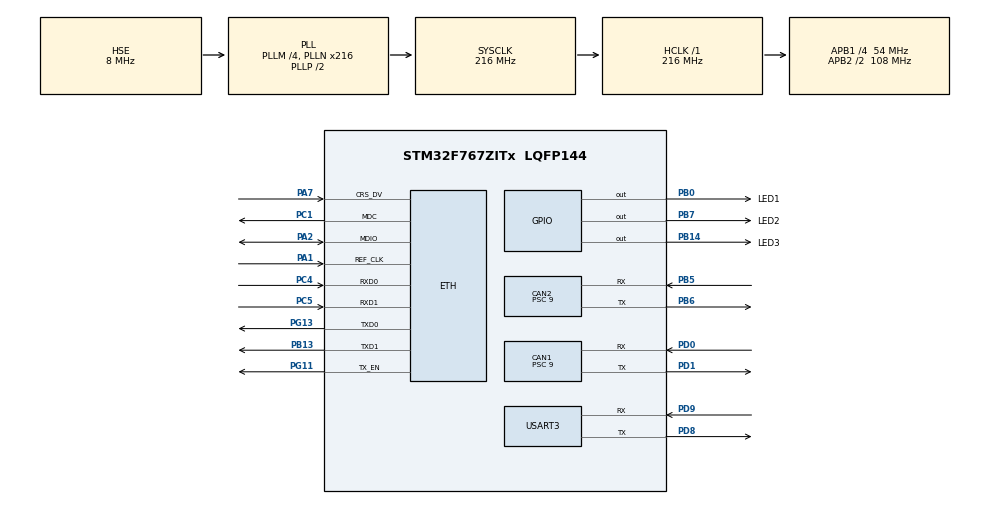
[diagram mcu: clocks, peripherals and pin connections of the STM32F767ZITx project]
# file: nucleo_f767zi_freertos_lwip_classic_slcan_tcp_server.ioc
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CAN1.ABOM=ENABLE
CAN1.BS1=CAN_BS1_6TQ
CAN1.BS2=CAN_BS2_5TQ
CAN1.CalculateBaudRate=499999
CAN1.CalculateTimeBit=2000
CAN1.CalculateTimeQuantum=166.66666666666669
CAN1.NART=ENABLE
CAN1.Prescaler=9
CAN1.TXFP=ENABLE
CAN2.ABOM=ENABLE
CAN2.BS1=CAN_BS1_6TQ
CAN2.BS2=CAN_BS2_5TQ
CAN2.CalculateBaudRate=499999
CAN2.CalculateTimeBit=2000
CAN2.CalculateTimeQuantum=166.66666666666669
CAN2.NART=ENABLE
CAN2.Prescaler=9
CAN2.TXFP=ENABLE
CORTEX_M7.default_mode_Activation=1
ETH.MediaInterface=HAL_ETH_RMII_MODE
FREERTOS.Tasks01=defaultTask,0,256,StartDefaultTask,Default,NULL,Dynamic,NULL,NULL
FREERTOS.configUSE_NEWLIB_REENTRANT=1
LWIP.BSP.number=1
LWIP.Version=v2.1.2_Cube
LWIP0.BSP.STBoard=false
LWIP0.BSP.api=BSP_COMPONENT_DRIVER
LWIP0.BSP.component=LAN8742
LWIP0.BSP.instance=LAN8742
LWIP0.BSP.name=Driver_PHY
LWIP0.BSP.semaphore=S_LAN8742
LWIP0.BSP.solution=LAN8742
Mcu.Family=STM32F7
Mcu.Name=STM32F767ZITx
Mcu.Package=LQFP144
NVIC.CAN1_RX0_IRQn=true\:5\:0\:false\:false\:true\:true\:true\:true\:true
NVIC.CAN1_RX1_IRQn=true\:5\:0\:false\:false\:true\:true\:true\:true\:true
NVIC.CAN1_SCE_IRQn=true\:5\:0\:false\:false\:true\:true\:true\:true\:true
NVIC.CAN1_TX_IRQn=true\:5\:0\:false\:false\:true\:true\:true\:true\:true
NVIC.CAN2_RX0_IRQn=true\:5\:0\:false\:false\:true\:true\:true\:true\:true
NVIC.CAN2_RX1_IRQn=true\:5\:0\:false\:false\:true\:true\:true\:true\:true
NVIC.CAN2_SCE_IRQn=true\:5\:0\:false\:false\:true\:true\:true\:true\:true
NVIC.CAN2_TX_IRQn=true\:5\:0\:false\:false\:true\:true\:true\:true\:true
NVIC.ETH_IRQn=true\:5\:0\:false\:false\:true\:true\:false\:true\:true
NVIC.PriorityGroup=NVIC_PRIORITYGROUP_4
NVIC.TIM8_TRG_COM_TIM14_IRQn=true\:15\:0\:false\:false\:true\:false\:false\:true\:true
NVIC.TimeBase=TIM8_TRG_COM_TIM14_IRQn
NVIC.TimeBaseIP=TIM14
PA1.Mode=RMII
PA1.Signal=ETH_REF_CLK
PA2.Mode=RMII
PA2.Signal=ETH_MDIO
PA7.Mode=RMII
PA7.Signal=ETH_CRS_DV
PB0.GPIO_Label=LED1
PB0.Signal=GPIO_Output
PB13.Mode=RMII
PB13.Signal=ETH_TXD1
PB14.GPIO_Label=LED3
PB14.Signal=GPIO_Output
PB5.Mode=CAN_Activate
PB5.Signal=CAN2_RX
PB6.Mode=CAN_Activate
PB6.Signal=CAN2_TX
PB7.GPIO_Label=LED2
PB7.Signal=GPIO_Output
PC1.Mode=RMII
PC1.Signal=ETH_MDC
PC4.Mode=RMII
PC4.Signal=ETH_RXD0
PC5.Mode=RMII
PC5.Signal=ETH_RXD1
PD0.Mode=CAN_Activate
PD0.Signal=CAN1_RX
PD1.Mode=CAN_Activate
PD1.Signal=CAN1_TX
PD8.Mode=Asynchronous
PD8.Signal=USART3_TX
PD9.Mode=Asynchronous
PD9.Signal=USART3_RX
PG11.Mode=RMII
PG11.Signal=ETH_TX_EN
PG13.Mode=RMII
PG13.Signal=ETH_TXD0
PH0/OSC_IN.Mode=HSE-External-Clock-Source
PH0/OSC_IN.Signal=RCC_OSC_IN
PH1/OSC_OUT.Mode=HSE-External-Clock-Source
PH1/OSC_OUT.Signal=RCC_OSC_OUT
ProjectManager.HeapSize=0x200
ProjectManager.StackSize=0x400
ProjectManager.TargetToolchain=STM32CubeIDE
RCC.AHBFreq_Value=216000000
RCC.APB1CLKDivider=RCC_HCLK_DIV4
RCC.APB1Freq_Value=54000000
RCC.APB1TimFreq_Value=108000000
RCC.APB2CLKDivider=RCC_HCLK_DIV2
RCC.APB2Freq_Value=108000000
RCC.APB2TimFreq_Value=216000000
RCC.CortexFreq_Value=216000000
RCC.HCLKFreq_Value=216000000
RCC.HSE_VALUE=8000000
RCC.HSI_VALUE=16000000
RCC.LSE_VALUE=32768
RCC.PLLM=4
RCC.PLLN=216
RCC.PLLSourceVirtual=RCC_PLLSOURCE_HSE
RCC.SYSCLKFreq_VALUE=216000000
RCC.SYSCLKSource=RCC_SYSCLKSOURCE_PLLCLK
RCC.USBFreq_Value=216000000
RCC.VCOOutputFreq_Value=432000000
USART3.VirtualMode-Asynchronous=VM_ASYNC
VP_FREERTOS_VS_CMSIS_V1.Mode=CMSIS_V1
VP_LWIP_VS_Enabled.Mode=Enabled
VP_SYS_VS_tim14.Mode=TIM14
board=custom

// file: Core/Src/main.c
/* USER CODE BEGIN Header */
/**
  ******************************************************************************
  * @file           : main.c
  * @brief          : Main program body
  ******************************************************************************
  * @attention
  *
  * Copyright (c) 2026 STMicroelectronics.
  * All rights reserved.
  *
  * This software is licensed under terms that can be found in the LICENSE file
  * in the root directory of this software component.
  * If no LICENSE file comes with this software, it is provided AS-IS.
  *
  ******************************************************************************
  */
/* USER CODE END Header */
#include "main.h"
#include "cmsis_os.h"
#include "can.h"
#include "lwip.h"
#include "usart.h"
#include "gpio.h"

/* USER CODE BEGIN Includes */
#include "can_app.h"
/* USER CODE END Includes */

void SystemClock_Config(void);
static void MPU_Config(void);
void MX_FREERTOS_Init(void);

int main(void)
{

  /* MPU Configuration--------------------------------------------------------*/
  MPU_Config();

  /* MCU Configuration--------------------------------------------------------*/

  /* Reset of all peripherals, Initializes the Flash interface and the Systick. */
  HAL_Init();

  /* Configure the system clock */
  SystemClock_Config();

  /* Initialize all configured peripherals */
  MX_GPIO_Init();
  MX_CAN1_Init();
  MX_CAN2_Init();
  MX_USART3_UART_Init();
  /* USER CODE BEGIN 2 */
  can_app_init();
  /* USER CODE END 2 */

  /* Call init function for freertos objects (in cmsis_os2.c) */
  MX_FREERTOS_Init();

  /* Start scheduler */
  osKernelStart();

  /* We should never get here as control is now taken by the scheduler */

  /* Infinite loop */
  while (1)
  {

  }
}

void SystemClock_Config(void)
{
  RCC_OscInitTypeDef RCC_OscInitStruct = {0};
  RCC_ClkInitTypeDef RCC_ClkInitStruct = {0};

  /** Configure the main internal regulator output voltage
  */
  __HAL_RCC_PWR_CLK_ENABLE();
  __HAL_PWR_VOLTAGESCALING_CONFIG(PWR_REGULATOR_VOLTAGE_SCALE1);

  /** Initializes the RCC Oscillators according to the specified parameters
  * in the RCC_OscInitTypeDef structure.
  */
  RCC_OscInitStruct.OscillatorType = RCC_OSCILLATORTYPE_HSE;
  RCC_OscInitStruct.HSEState = RCC_HSE_BYPASS;
  RCC_OscInitStruct.PLL.PLLState = RCC_PLL_ON;
  RCC_OscInitStruct.PLL.PLLSource = RCC_PLLSOURCE_HSE;
  RCC_OscInitStruct.PLL.PLLM = 4;
  RCC_OscInitStruct.PLL.PLLN = 216;
  RCC_OscInitStruct.PLL.PLLP = RCC_PLLP_DIV2;
  RCC_OscInitStruct.PLL.PLLQ = 2;
  RCC_OscInitStruct.PLL.PLLR = 2;
  if (HAL_RCC_OscConfig(&RCC_OscInitStruct) != HAL_OK)
  {
    Error_Handler();
  }

  /** Activate the Over-Drive mode
  */
  if (HAL_PWREx_EnableOverDrive() != HAL_OK)
  {
    Error_Handler();
  }

  /** Initializes the CPU, AHB and APB buses clocks
  */
  RCC_ClkInitStruct.ClockType = RCC_CLOCKTYPE_HCLK|RCC_CLOCKTYPE_SYSCLK
                              |RCC_CLOCKTYPE_PCLK1|RCC_CLOCKTYPE_PCLK2;
  RCC_ClkInitStruct.SYSCLKSource = RCC_SYSCLKSOURCE_PLLCLK;
  RCC_ClkInitStruct.AHBCLKDivider = RCC_SYSCLK_DIV1;
  RCC_ClkInitStruct.APB1CLKDivider = RCC_HCLK_DIV4;
  RCC_ClkInitStruct.APB2CLKDivider = RCC_HCLK_DIV2;

  if (HAL_RCC_ClockConfig(&RCC_ClkInitStruct, FLASH_LATENCY_7) != HAL_OK)
  {
    Error_Handler();
  }
}

 /* MPU Configuration */

void MPU_Config(void)
{
  MPU_Region_InitTypeDef MPU_InitStruct = {0};

  /* Disables the MPU */
  HAL_MPU_Disable();

  /** Initializes and configures the Region and the memory to be protected
  */
  MPU_InitStruct.Enable = MPU_REGION_ENABLE;
  MPU_InitStruct.Number = MPU_REGION_NUMBER0;
  MPU_InitStruct.BaseAddress = 0x0;
  MPU_InitStruct.Size = MPU_REGION_SIZE_4GB;
  MPU_InitStruct.SubRegionDisable = 0x87;
  MPU_InitStruct.TypeExtField = MPU_TEX_LEVEL0;
  MPU_InitStruct.AccessPermission = MPU_REGION_NO_ACCESS;
  MPU_InitStruct.DisableExec = MPU_INSTRUCTION_ACCESS_DISABLE;
  MPU_InitStruct.IsShareable = MPU_ACCESS_SHAREABLE;
  MPU_InitStruct.IsCacheable = MPU_ACCESS_NOT_CACHEABLE;
  MPU_InitStruct.IsBufferable = MPU_ACCESS_NOT_BUFFERABLE;

  HAL_MPU_ConfigRegion(&MPU_InitStruct);
  /* Enables the MPU */
  HAL_MPU_Enable(MPU_PRIVILEGED_DEFAULT);

}

void HAL_TIM_PeriodElapsedCallback(TIM_HandleTypeDef *htim)
{
  if (htim->Instance == TIM14)
  {
    HAL_IncTick();
  }
}

void Error_Handler(void)
{
  __disable_irq();
  while (1)
  {
  }
}

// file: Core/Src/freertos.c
/* USER CODE BEGIN Header */
/**
  ******************************************************************************
  * File Name          : freertos.c
  * Description        : Code for freertos applications
  ******************************************************************************
  * @attention
  *
  * Copyright (c) 2026 STMicroelectronics.
  * All rights reserved.
  *
  * This software is licensed under terms that can be found in the LICENSE file
  * in the root directory of this software component.
  * If no LICENSE file comes with this software, it is provided AS-IS.
  *
  ******************************************************************************
  */
/* USER CODE END Header */

#include "FreeRTOS.h"
#include "task.h"
#include "main.h"
#include "cmsis_os.h"

/* USER CODE BEGIN Includes */
#include "can_app_tcp.h"

/* USER CODE END Includes */

osThreadId defaultTaskHandle;

void StartDefaultTask(void const * argument);

extern void MX_LWIP_Init(void);
void MX_FREERTOS_Init(void); /* (MISRA C 2004 rule 8.1) */

/* GetIdleTaskMemory prototype (linked to static allocation support) */
void vApplicationGetIdleTaskMemory( StaticTask_t **ppxIdleTaskTCBBuffer, StackType_t **ppxIdleTaskStackBuffer, uint32_t *pulIdleTaskStackSize );

/* USER CODE BEGIN GET_IDLE_TASK_MEMORY */
static StaticTask_t xIdleTaskTCBBuffer;
static StackType_t xIdleStack[configMINIMAL_STACK_SIZE];

void vApplicationGetIdleTaskMemory( StaticTask_t **ppxIdleTaskTCBBuffer, StackType_t **ppxIdleTaskStackBuffer, uint32_t *pulIdleTaskStackSize )
{
  *ppxIdleTaskTCBBuffer = &xIdleTaskTCBBuffer;
  *ppxIdleTaskStackBuffer = &xIdleStack[0];
  *pulIdleTaskStackSize = configMINIMAL_STACK_SIZE;
  /* place for user code */
}
/* USER CODE END GET_IDLE_TASK_MEMORY */

void MX_FREERTOS_Init(void) {

  /* Create the thread(s) */
  /* definition and creation of defaultTask */
  osThreadDef(defaultTask, StartDefaultTask, osPriorityNormal, 0, 256);
  defaultTaskHandle = osThreadCreate(osThread(defaultTask), NULL);

}

void StartDefaultTask(void const * argument)
{
  /* init code for LWIP */
  MX_LWIP_Init();
  /* USER CODE BEGIN StartDefaultTask */
  can_app_tcp_start();
  /* Infinite loop */
  for(;;)
  {
    osDelay(1);
  }
  /* USER CODE END StartDefaultTask */
}
